VERSION "FMS standard seed"

NS_ :

BS_:

BU_: Vector__XXX

BO_ 2566843409 VI: 8 Vector__XXX

BO_ 2566846225 VEP: 8 Vector__XXX
SG_ BatteryPotential_PowerInput1 : 32|16@1+ (0.05,0) [0|3276.75] "" Vector__XXX

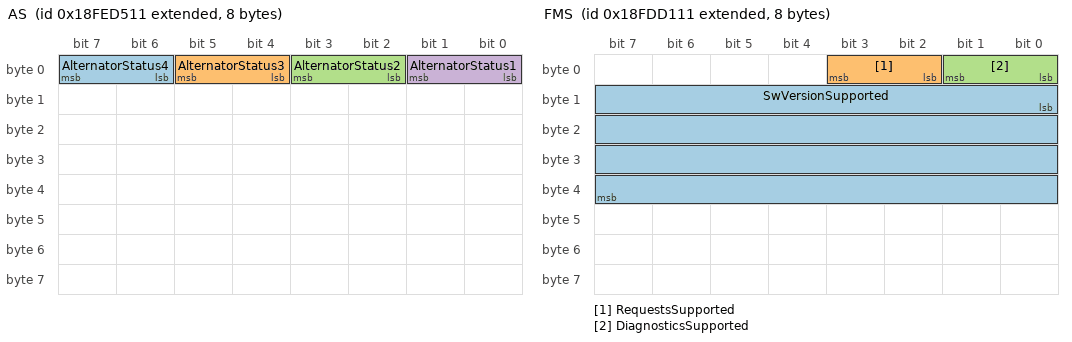
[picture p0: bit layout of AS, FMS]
BO_ 2566837521 AS: 8 Vector__XXX
SG_ AlternatorStatus4 : 6|2@1+ (1,0) [0|3] "" Vector__XXX
SG_ AlternatorStatus3 : 4|2@1+ (1,0) [0|3] "" Vector__XXX
SG_ AlternatorStatus2 : 2|2@1+ (1,0) [0|3] "" Vector__XXX
SG_ AlternatorStatus1 : 0|2@1+ (1,0) [0|3] "" Vector__XXX

BO_ 2566810385 DI: 8 Vector__XXX
SG_ Driver2Identification : 8|8@1+ (1,0) [0|255] "" Vector__XXX
SG_ Driver1Identification : 0|8@1+ (1,0) [0|255] "" Vector__XXX

BO_ 2566805521 ASC4: 8 Vector__XXX

BO_ 2566770961 FMS: 8 Vector__XXX
SG_ SwVersionSupported : 8|32@1+ (1,0) [0|4294967295] "" Vector__XXX
SG_ RequestsSupported : 2|2@1+ (1,0) [0|3] "" Vector__XXX
SG_ DiagnosticsSupported : 0|2@1+ (1,0) [0|3] "" Vector__XXX

BO_ 2566698769 VEP4: 8 Vector__XXX
SG_ HybridBatteryPackRemainingCharge : 0|16@1+ (0.0025,0) [0|163.8375] "" Vector__XXX

BO_ 2565865489 ERC1: 8 Vector__XXX
SG_ ERC1_WheelBasedSpeed : 8|16@1+ (0.00390625,0) [0|255.99609375] "km/h" Vector__XXX

BO_ 2566719761 HRLFC: 8 Vector__XXX
SG_ HighResolutionEngineTotFuelUsed : 32|32@1+ (0.001,0) [0|4294967.295] "L" Vector__XXX

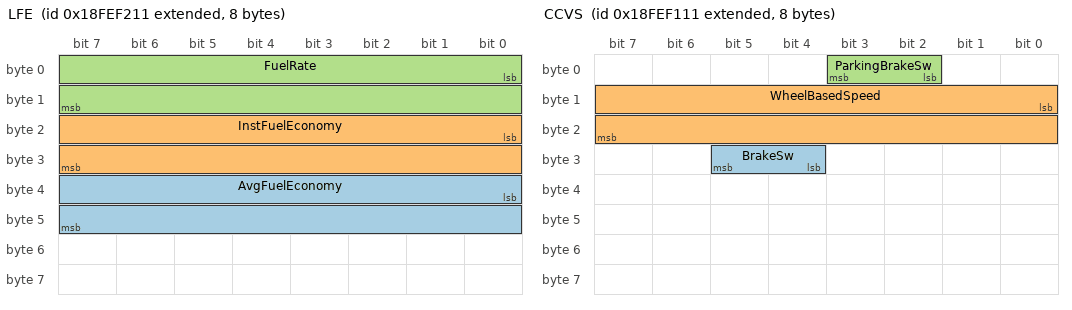
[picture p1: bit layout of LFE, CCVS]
BO_ 2566844945 LFE: 8 Vector__XXX
SG_ AvgFuelEconomy : 32|16@1+ (0.00195312,0) [0|127.9977192] "km/L" Vector__XXX
SG_ InstFuelEconomy : 16|16@1+ (0.00195312,0) [0|127.9977192] "km/L" Vector__XXX
SG_ FuelRate : 0|16@1+ (0.05,0) [0|3276.75] "L/h" Vector__XXX

BO_ 2566843921 ET1: 8 Vector__XXX
SG_ EngineFuelTemperature : 8|8@1+ (1,-40) [-40|215] "°C" Vector__XXX
SG_ EngineCoolantTemperature : 0|8@1+ (1,-40) [-40|215] "°C" Vector__XXX

BO_ 2566847511 DD1: 8 Vector__XXX
SG_ FuelLevel2 : 48|8@1+ (0.4,0) [0|102] "%" Vector__XXX
SG_ FuelLevel1 : 8|8@1+ (0.4,0) [0|102] "%" Vector__XXX

BO_ 2566842641 LFC: 8 Vector__XXX
SG_ EngineTotalFuelUsed : 32|32@1+ (0.5,0) [0|2147483647.5] "" Vector__XXX

BO_ 2565865739 EBC1: 8 Vector__XXX
SG_ BrakePedalPos : 8|8@1+ (0.4,0) [0|100] "%" Vector__XXX

BO_ 2565866755 ETC2: 8 Vector__XXX
SG_ CurrentGear : 24|8@1+ (1,-125) [-125|130] "" Vector__XXX
SG_ SelectedGear : 0|8@1+ (1,-125) [-125|130] "" Vector__XXX

BO_ 2566844689 CCVS: 8 Vector__XXX
SG_ BrakeSw : 28|2@1+ (1,0) [0|3] "" Vector__XXX
SG_ WheelBasedSpeed : 8|16@1+ (0.00390625,0) [0|255.99609375] "km/h" Vector__XXX
SG_ ParkingBrakeSw : 2|2@1+ (1,0) [0|3] "" Vector__XXX

BO_ 2566832622 VHDR: 8 Vector__XXX
SG_ HighResolutionVehicleDistance : 0|32@1+ (0.005,0) [0|21474836.475] "km" Vector__XXX

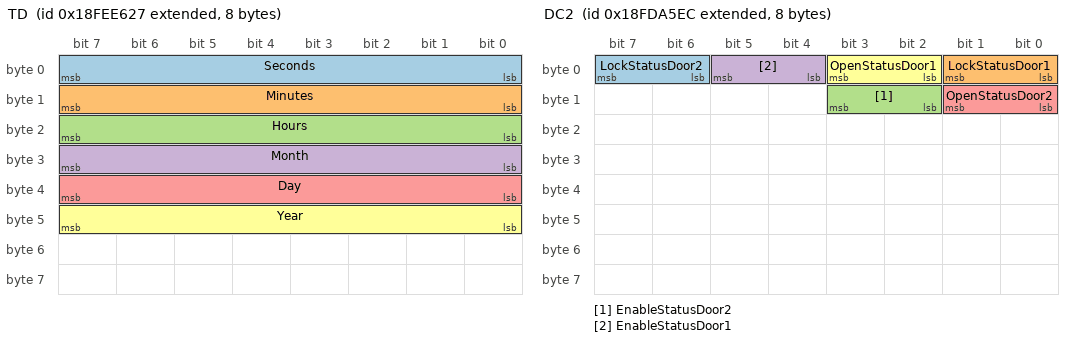
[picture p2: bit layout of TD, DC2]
BO_ 2566841895 TD: 8 Vector__XXX
SG_ Seconds : 0|8@1+ (0.25,0) [0|60] "" Vector__XXX
SG_ Minutes : 8|8@1+ (1,0) [0|60] "" Vector__XXX
SG_ Hours : 16|8@1+ (1,0) [0|24] "" Vector__XXX
SG_ Month : 24|8@1+ (1,0) [0|12] "" Vector__XXX
SG_ Day : 32|8@1+ (0.25,0) [0|31] "" Vector__XXX
SG_ Year : 40|8@1+ (1,1807) [1807|2062] "" Vector__XXX

BO_ 2566759916 DC2: 8 Vector__XXX
SG_ LockStatusDoor2 : 6|2@1+ (1,0) [0|3] "" Vector__XXX
SG_ LockStatusDoor1 : 0|2@1+ (1,0) [0|3] "" Vector__XXX
SG_ EnableStatusDoor2 : 10|2@1+ (1,0) [0|3] "" Vector__XXX
SG_ EnableStatusDoor1 : 4|2@1+ (1,0) [0|3] "" Vector__XXX
SG_ OpenStatusDoor2 : 8|2@1+ (1,0) [0|3] "" Vector__XXX
SG_ OpenStatusDoor1 : 2|2@1+ (1,0) [0|3] "" Vector__XXX

BO_ 2566827568 AIR1: 8 Vector__XXX
SG_ Service_Brake_Air_Pressure2 : 24|8@1+ (8,0) [0|2040] "" Vector__XXX
SG_ Service_Brake_Air_Pressure1 : 16|8@1+ (8,0) [0|2040] "" Vector__XXX

BO_ 2566845735 AMB: 8 Vector__XXX
SG_ AMB_CabInteriorTemp : 8|16@1+ (0.03125,-273) [-273|1774.96875] "°C" Vector__XXX
SG_ AMB_AirTemp : 24|16@1+ (0.03125,-273) [-273|1774.96875] "°C" Vector__XXX

BO_ 2365484270 TCO1: 8 Vector__XXX
SG_ TachoVehicleSpeed : 48|16@1+ (0.0039,0) [0|255.5865] "km/h" Vector__XXX

BO_ 2566841617 HOURS: 8 Vector__XXX
SG_ EngineTotalRevolutions : 32|32@1+ (1000,0) [0|4294967295000] "r" Vector__XXX
SG_ MotorTotHours : 0|32@1+ (0.05,0) [0|214748364.75] "hours" Vector__XXX

BO_ 2364539648 EEC2: 8 Vector__XXX
SG_ AccPedalKickdownSw : 2|2@1+ (1,0) [0|3] "" Vector__XXX
SG_ AccPedalPos : 8|8@1+ (0.4,0) [0|100] "%" Vector__XXX

BO_ 2364539904 EEC1: 8 Vector__XXX
SG_ ActualEngine_PercentTorque : 16|8@1+ (1,-125) [-100|100] "%" Vector__XXX
SG_ MotorSpeed : 24|16@1+ (0.125,0) [0|8191.875] "rpm" Vector__XXX

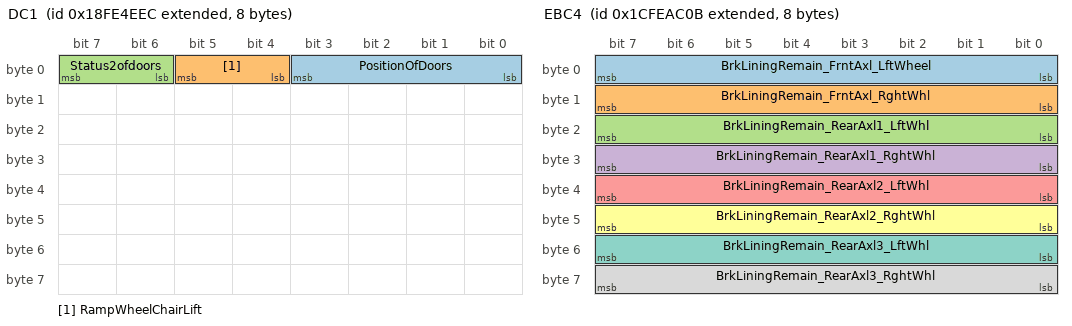
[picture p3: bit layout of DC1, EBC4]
BO_ 2566803180 DC1: 8 Vector__XXX
SG_ PositionOfDoors : 0|4@1+ (1,0) [0|15] "" Vector__XXX
SG_ RampWheelChairLift : 4|2@1+ (1,0) [0|3] "" Vector__XXX
SG_ Status2ofdoors : 6|2@1+ (1,0) [0|1] "" Vector__XXX

BO_ 2566749457 FMS1: 1 Vector__XXX
SG_ FMS1_Mux M : 0|4@1+ (1,0) [0|0] "" Vector__XXX

BO_ 2565867787 VDC2: 8 Vector__XXX
SG_ LongitudinalAcceleration : 56|8@1+ (0.1,-12.5) [-12.5|12.5] "m/s^2" Vector__XXX

BO_ 2566842366 VH: 8 Vector__XXX
SG_ TotalVehicleHours : 0|32@1+ (0.05,0) [0|210554060.75] "hr" Vector__XXX
SG_ TotalPowerTakeoffHours : 32|32@1+ (0.05,0) [0|210554060.75] "hr" Vector__XXX

BO_ 2633935883 EBC4: 8 Vector__XXX
SG_ BrkLiningRemain_FrntAxl_LftWheel : 0|8@1+ (0.4,0) [0|100] "%" Vector__XXX
SG_ BrkLiningRemain_FrntAxl_RghtWhl : 8|8@1+ (0.4,0) [0|100] "%" Vector__XXX
SG_ BrkLiningRemain_RearAxl1_LftWhl : 16|8@1+ (0.4,0) [0|100] "%" Vector__XXX
SG_ BrkLiningRemain_RearAxl1_RghtWhl : 24|8@1+ (0.4,0) [0|100] "%" Vector__XXX
SG_ BrkLiningRemain_RearAxl2_LftWhl : 32|8@1+ (0.4,0) [0|100] "%" Vector__XXX
SG_ BrkLiningRemain_RearAxl2_RghtWhl : 40|8@1+ (0.4,0) [0|100] "%" Vector__XXX
SG_ BrkLiningRemain_RearAxl3_LftWhl : 48|8@1+ (0.4,0) [0|100] "%" Vector__XXX
SG_ BrkLiningRemain_RearAxl3_RghtWhl : 56|8@1+ (0.4,0) [0|100] "%" Vector__XXX

BO_ 2566834718 DM01_BMS: 14 Vector__XXX
SG_ ProtectLamp : 0|2@1+ (1,0) [0|3] "" Vector__XXX
SG_ AmberWarningLamp : 2|2@1+ (1,0) [0|3] "" Vector__XXX
SG_ RedStopLamp : 4|2@1+ (1,0) [0|3] "" Vector__XXX
SG_ MalfunctionIndicatorLamp : 6|2@1+ (1,0) [0|3] "" Vector__XXX
SG_ FlashProtectLamp : 8|2@1+ (1,0) [0|3] "" Vector__XXX
SG_ FlashAmberWarningLamp : 10|2@1+ (1,0) [0|3] "" Vector__XXX
SG_ FlashRedStopLamp : 12|2@1+ (1,0) [0|3] "" Vector__XXX
SG_ FlashMalfunctionIndicatorLamp : 14|2@1+ (1,0) [0|3] "" Vector__XXX
SG_ SPN0msb : 37|3@1+ (1,0) [0|1] "" Vector__XXX
SG_ SPN1msb : 69|3@1+ (1,0) [0|1] "" Vector__XXX
SG_ SPN2msb : 101|3@1+ (1,0) [0|1] "" Vector__XXX
SG_ SPN0 : 16|16@1+ (1,0) [0|65535] "" Vector__XXX
SG_ SPN1 : 48|16@1+ (1,0) [0|65535] "" Vector__XXX
SG_ SPN2 : 80|16@1+ (1,0) [0|65535] "" Vector__XXX
SG_ FMI0 : 32|5@1+ (1,0) [0|31] "" Vector__XXX
SG_ FMI1 : 64|5@1+ (1,0) [0|31] "" Vector__XXX
SG_ FMI2 : 96|5@1+ (1,0) [0|31] "" Vector__XXX
SG_ OccurrenceCount0 : 40|7@1+ (1,0) [0|127] "" Vector__XXX
SG_ OccurrenceCount1 : 72|7@1+ (1,0) [0|127] "" Vector__XXX
SG_ OccurrenceCount2 : 104|7@1+ (1,0) [0|127] "" Vector__XXX
SG_ SPNConversionMethod0 : 47|1@1+ (1,0) [0|1] "" Vector__XXX
SG_ SPNConversionMethod1 : 79|1@1+ (1,0) [0|1] "" Vector__XXX
SG_ SPNConversionMethod2 : 111|1@1+ (1,0) [0|1] "" Vector__XXX

BO_ 2566834694 DM01_RHCV: 14 Vector__XXX
SG_ ProtectLamp : 0|2@1+ (1,0) [0|3] "" Vector__XXX
SG_ AmberWarningLamp : 2|2@1+ (1,0) [0|3] "" Vector__XXX
SG_ RedStopLamp : 4|2@1+ (1,0) [0|3] "" Vector__XXX
SG_ MalfunctionIndicatorLamp : 6|2@1+ (1,0) [0|3] "" Vector__XXX
SG_ FlashProtectLamp : 8|2@1+ (1,0) [0|3] "" Vector__XXX
SG_ FlashAmberWarningLamp : 10|2@1+ (1,0) [0|3] "" Vector__XXX
SG_ FlashRedStopLamp : 12|2@1+ (1,0) [0|3] "" Vector__XXX
SG_ FlashMalfunctionIndicatorLamp : 14|2@1+ (1,0) [0|3] "" Vector__XXX
SG_ SPN0msb : 37|3@1+ (1,0) [0|1] "" Vector__XXX
SG_ SPN1msb : 69|3@1+ (1,0) [0|1] "" Vector__XXX
SG_ SPN2msb : 101|3@1+ (1,0) [0|1] "" Vector__XXX
SG_ SPN0 : 16|16@1+ (1,0) [0|65535] "" Vector__XXX
SG_ SPN1 : 48|16@1+ (1,0) [0|65535] "" Vector__XXX
SG_ SPN2 : 80|16@1+ (1,0) [0|65535] "" Vector__XXX
SG_ FMI0 : 32|5@1+ (1,0) [0|31] "" Vector__XXX
SG_ FMI1 : 64|5@1+ (1,0) [0|31] "" Vector__XXX
SG_ FMI2 : 96|5@1+ (1,0) [0|31] "" Vector__XXX
SG_ OccurrenceCount0 : 40|7@1+ (1,0) [0|127] "" Vector__XXX
SG_ OccurrenceCount1 : 72|7@1+ (1,0) [0|127] "" Vector__XXX
SG_ OccurrenceCount2 : 104|7@1+ (1,0) [0|127] "" Vector__XXX
SG_ SPNConversionMethod0 : 47|1@1+ (1,0) [0|1] "" Vector__XXX
SG_ SPNConversionMethod1 : 79|1@1+ (1,0) [0|1] "" Vector__XXX
SG_ SPNConversionMethod2 : 111|1@1+ (1,0) [0|1] "" Vector__XXX

BO_ 2566834735 DM01_ECAS: 8 Vector__XXX
SG_ ProtectLamp_ECAS : 0|2@1+ (1,0) [0|3] "" Vector__XXX
SG_ AmberWarningLamp_ECAS : 2|2@1+ (1,0) [0|3] "" Vector__XXX
SG_ RedStopLamp_ECAS : 4|2@1+ (1,0) [0|3] "" Vector__XXX
SG_ MalfunctionIndicatorLamp_ECAS : 6|2@1+ (1,0) [0|3] "" Vector__XXX
SG_ FlashProtectLamp_ECAS : 8|2@1+ (1,0) [0|3] "" Vector__XXX
SG_ FlashAmberWarningLamp_ECAS : 10|2@1+ (1,0) [0|3] "" Vector__XXX
SG_ FlashRedStopLamp_ECAS : 12|2@1+ (1,0) [0|3] "" Vector__XXX
SG_ FlashMalfunctionIndicatorLamp_ECAS : 14|2@1+ (1,0) [0|3] "" Vector__XXX
SG_ SPN0msb_ECAS : 37|3@1+ (1,0) [0|1] "" Vector__XXX
SG_ SPN1msb_ECAS : 69|3@1+ (1,0) [0|1] "" Vector__XXX
SG_ SPN2msb_ECAS : 101|3@1+ (1,0) [0|1] "" Vector__XXX
SG_ SPN0_ECAS : 16|16@1+ (1,0) [0|65535] "" Vector__XXX
SG_ SPN1_ECAS : 48|16@1+ (1,0) [0|65535] "" Vector__XXX
SG_ SPN2_ECAS : 80|16@1+ (1,0) [0|65535] "" Vector__XXX
SG_ FMI0_ECAS : 32|5@1+ (1,0) [0|31] "" Vector__XXX
SG_ FMI1_ECAS : 64|5@1+ (1,0) [0|31] "" Vector__XXX
SG_ FMI2_ECAS : 96|5@1+ (1,0) [0|31] "" Vector__XXX
SG_ OccurrenceCount0_ECAS : 40|7@1+ (1,0) [0|127] "" Vector__XXX
SG_ OccurrenceCount1_ECAS : 72|7@1+ (1,0) [0|127] "" Vector__XXX
SG_ OccurrenceCount2_ECAS : 104|7@1+ (1,0) [0|127] "" Vector__XXX
SG_ SPNConversionMethod0_ECAS : 47|1@1+ (1,0) [0|1] "" Vector__XXX
SG_ SPNConversionMethod1_ECAS : 79|1@1+ (1,0) [0|1] "" Vector__XXX
SG_ SPNConversionMethod2_ECAS : 111|1@1+ (1,0) [0|1] "" Vector__XXX

CM_ SG_ 2566841617 MotorTotHours "Engine total hours of Operation: Accumulated time of operation of engine.";
CM_ BO_ 2565867787 "Vehicle Dynamic Stability Control 2";
CM_ BO_ 2566842366 "Vehicle Hours";
CM_ BO_ 2633935883 "Wheel Brake Lining Remaining Information";
CM_ BO_ 2566834718 "Codici Errore Diagnostici Attivi";
CM_ BO_ 2566834694 "Codici Errore Diagnostici Attivi";

VAL_ 2565865489 ERC1_WheelBasedSpeed 256 "N.A";
VAL_ 2566844689 BrakeSw 1 "Pedal Dereleased" 0 "Pedal Released";
VAL_ 2566844689 WheelBasedSpeed 256 "N.A";
VAL_ 2566844689 ParkingBrakeSw 1 "Parking Brake Set" 0 "Parking Brake Not Set";
VAL_ 2566749457 FMS1_Mux 3 "BLOCK ID 3" 2 "BLOCK ID 2" 1 "BLOCK ID 1" 0 "BLOCK ID 0";
VAL_ 2566834718 ProtectLamp 0 "Lamp Off" 1 "Lamp On" 2 "Reserved" 3 "Not available";
VAL_ 2566834718 AmberWarningLamp 0 "Lamp Off" 1 "Lamp On" 2 "Reserved" 3 "Not available";
VAL_ 2566834718 RedStopLamp 0 "Lamp Off" 1 "Lamp On" 2 "Reserved" 3 "Not available";
VAL_ 2566834718 MalfunctionIndicatorLamp 0 "Lamp Off" 1 "Lamp On" 2 "Short MIL for WWH OBD" 3 "Not available";
VAL_ 2566834718 FlashProtectLamp 0 "Slow Flash (1 Hz, 50 % duty cycle)" 1 "Fast Flash (2 Hz or faster, 50% duty cycle)" 2 "Reserved" 3 "Unavailable / Do Not Flash";
VAL_ 2566834718 FlashAmberWarningLamp 0 "Slow Flash (1 Hz, 50 % duty cycle)" 1 "Fast Flash (2 Hz or faster, 50% duty cycle)" 2 "Reserved" 3 "Unavailable / Do Not Flash";
VAL_ 2566834718 FlashRedStopLamp 0 "Slow Flash (1 Hz, 50 % duty cycle)" 1 "Fast Flash (2 Hz or faster, 50% duty cycle)" 2 "Reserved" 3 "Unavailable / Do Not Flash";
VAL_ 2566834718 FlashMalfunctionIndicatorLamp 0 "Slow Flash (1 Hz, 50 % duty cycle)" 1 "Fast Flash (2 Hz or faster, 50% duty cycle)" 2 "Class C DTC  " 3 "Unavailable / Do Not Flash";
VAL_ 2566834718 SPNConversionMethod0 0 "Convert SPN per Version 4" 1 "Convert SPN per Version 1, 2 or 3";
VAL_ 2566834718 SPNConversionMethod1 0 "Convert SPN per Version 4" 1 "Convert SPN per Version 1, 2 or 3";
VAL_ 2566834718 SPNConversionMethod2 0 "Convert SPN per Version 4" 1 "Convert SPN per Version 1, 2 or 3";
VAL_ 2566834694 ProtectLamp 0 "Lamp Off" 1 "Lamp On" 2 "Reserved" 3 "Not available";
VAL_ 2566834694 AmberWarningLamp 0 "Lamp Off" 1 "Lamp On" 2 "Reserved" 3 "Not available";
VAL_ 2566834694 RedStopLamp 0 "Lamp Off" 1 "Lamp On" 2 "Reserved" 3 "Not available";
VAL_ 2566834694 MalfunctionIndicatorLamp 0 "Lamp Off" 1 "Lamp On" 2 "Short MIL for WWH OBD" 3 "Not available";
VAL_ 2566834694 FlashProtectLamp 0 "Slow Flash (1 Hz, 50 % duty cycle)" 1 "Fast Flash (2 Hz or faster, 50% duty cycle)" 2 "Reserved" 3 "Unavailable / Do Not Flash";
VAL_ 2566834694 FlashAmberWarningLamp 0 "Slow Flash (1 Hz, 50 % duty cycle)" 1 "Fast Flash (2 Hz or faster, 50% duty cycle)" 2 "Reserved" 3 "Unavailable / Do Not Flash";
VAL_ 2566834694 FlashRedStopLamp 0 "Slow Flash (1 Hz, 50 % duty cycle)" 1 "Fast Flash (2 Hz or faster, 50% duty cycle)" 2 "Reserved" 3 "Unavailable / Do Not Flash";
VAL_ 2566834694 FlashMalfunctionIndicatorLamp 0 "Slow Flash (1 Hz, 50 % duty cycle)" 1 "Fast Flash (2 Hz or faster, 50% duty cycle)" 2 "Class C DTC  " 3 "Unavailable / Do Not Flash";
VAL_ 2566834694 SPNConversionMethod0 0 "Convert SPN per Version 4" 1 "Convert SPN per Version 1, 2 or 3";
VAL_ 2566834694 SPNConversionMethod1 0 "Convert SPN per Version 4" 1 "Convert SPN per Version 1, 2 or 3";
VAL_ 2566834694 SPNConversionMethod2 0 "Convert SPN per Version 4" 1 "Convert SPN per Version 1, 2 or 3";
